# STM32H5F5 register map
File version: 1.0
CPU: CM33 r0p0, little endian, MPU, FPU, 4 interrupt priority bits
Registers are 32-bit, read-write, reset 0x0 unless marked. A register's access mark holds for its fields unless they carry their own. Offsets are from the block's base; [hi:lo] are bit positions; {n}, {i} and the like mark numbered series; 'fields as' and 'values as' point back to an identical list.

## FMC — FMC address block description
Base 0x47000400
Same registers: FMC_S 0x57000400
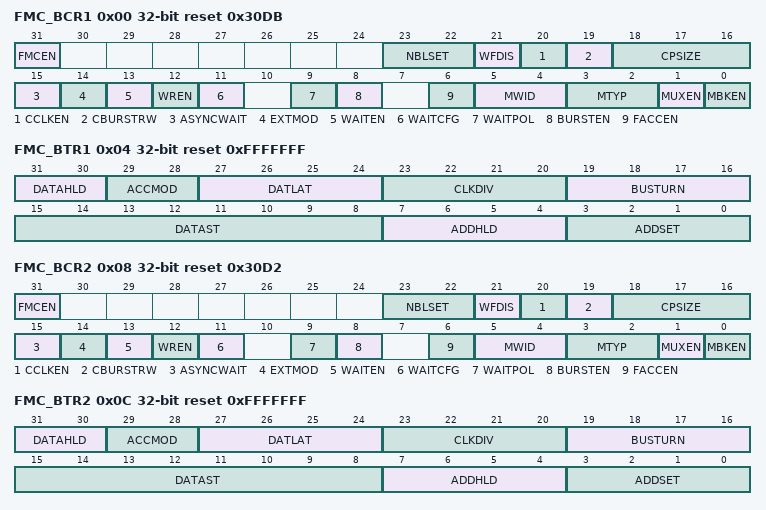
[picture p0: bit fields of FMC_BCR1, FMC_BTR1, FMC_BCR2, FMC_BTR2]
0x00 FMC_BCR1 reset 0x30DB — SRAM/NOR-flash chip-select control register for bank 1
  [31] FMCEN — FMC controller enable
    0=Disable the FMC controller; 1=Enable the FMC controller
  [23:22] NBLSET — Byte lane (NBL) setup
    0=NBL setup time is 0 AHB clock cycle; 1=NBL setup time is 1 AHB clock cycle; 2=NBL setup time is 2 AHB clock cycles; 3=NBL setup time is 3 AHB clock cycles
  [21] WFDIS — Write FIFO disable
    0=Write FIFO enabled (Default after reset); 1=Write FIFO disabled
  [20] CCLKEN — Continuous clock enable
    0=The FMC_CLK is only generated during the synchronous memory access (read/write transaction); 1=The FMC_CLK is generated continuously during asynchronous and synchronous access
  [19] CBURSTRW — Write burst enable
    0=Write operations are always performed in Asynchronous mode; 1=Write operations are performed in Synchronous mode
  [18:16] CPSIZE — CRAM page size
    0=No burst split when crossing page boundary (default after reset); 1=128 bytes; 2=256 bytes; 3=512 bytes; 4=1024 bytes
  [15] ASYNCWAIT — Wait signal during asynchronous transfers
    0=NWAIT signal is not taken in to account when running an asynchronous protocol (default after reset); 1=NWAIT signal is taken in to account when running an asynchronous protocol
  [14] EXTMOD — Extended mode enable
    0=values inside FMC_BWTR register are not taken into account (default after reset); 1=values inside FMC_BWTR register are taken into account
  [13] WAITEN — Wait enable bit
    0=NWAIT signal is disabled (its level not taken into account, no wait state inserted after the programmed flash latency period); 1=NWAIT signal is enabled (its level is taken into account after the programmed latency period to insert wait states if asserted) (default after reset)
  [12] WREN — Write enable bit
    0=Write operations are disabled in the bank by the FMC, an AHB error is reported; 1=Write operations are enabled for the bank by the FMC (default after reset)
  [11] WAITCFG — Wait timing configuration
    0=NWAIT signal is active one data cycle before wait state (default after reset); 1=NWAIT signal is active during wait state (not used for PSRAM)
  [9] WAITPOL — Wait signal polarity bit
    0=NWAIT active low (default after reset); 1=NWAIT active high
  [8] BURSTEN — Burst enable bit
    0=Burst mode disabled (default after reset); 1=Burst mode enable
  [6] FACCEN — Flash access enable
    0=Corresponding NOR flash memory access is disabled; 1=Corresponding NOR flash memory access is enabled (default after reset)
  [5:4] MWID — Memory data bus width
    0=8 bits; 1=16 bits (default after reset); 2=32 bits
  [3:2] MTYP — Memory type
    0=SRAM/FRAM (default after reset for Bank 2; 1=PSRAM (CRAM) / FRAM; 2=NOR flash/OneNAND flash (default after reset for Bank 1)
  [1] MUXEN — Address/data multiplexing enable bit
    0=Address/data non multiplexed; 1=Address/data multiplexed on databus (default after reset)
  [0] MBKEN — Memory bank enable bit
    0=Corresponding memory bank is disabled; 1=Corresponding memory bank is enabled
0x04 FMC_BTR1 reset 0xFFFFFFF — SRAM/NOR-flash chip-select timing register for bank 1
  [31:30] DATAHLD — Data hold phase duration
    0=DATAHLD phase duration = 1 x HCLK clock cycle (default); 1=DATAHLD phase duration = 2 x HCLK clock cycle; 2=DATAHLD phase duration = 3 x HCLK clock cycle; 3=DATAHLD phase duration = 4 x HCLK clock cycle
  [29:28] ACCMOD — Access mode
    0=Access mode A; 1=Access mode B; 2=Access mode C; 3=Access mode D
  [27:24] DATLAT — (see note below bit descriptions): Data latency for synchronous memory
    0=Data latency of 2 CLK clock cycles for first burst access; 15=Data latency of 17 CLK clock cycles for first burst access (default value after reset)
  [23:20] CLKDIV — Clock divide ratio (for FMC_CLK signal)
    0=FMC_CLK period= 1x HCLK period; 1=FMC_CLK period = 2 x HCLK periods; 2=FMC_CLK period = 3 x HCLK periods; 15=FMC_CLK period = 16 x HCLK periods (default value after reset)
  [19:16] BUSTURN — Bus turnaround phase duration
    0=BUSTURN phase duration = 1 HCLK clock cycle added; 15=BUSTURN phase duration = 16 x HCLK clock cycles added (default value after reset)
  [15:8] DATAST — Data-phase duration
    1=DATAST phase duration = 1 x HCLK clock cycles; 2=DATAST phase duration = 2 x HCLK clock cycles; 255=DATAST phase duration = 255 x HCLK clock cycles (default value after reset)
  [7:4] ADDHLD — Address-hold phase duration
    1=ADDHLD phase duration =1 x HCLK clock cycle; 2=ADDHLD phase duration = 2 x HCLK clock cycle; 15=ADDHLD phase duration = 15 x HCLK clock cycles (default value after reset)
  [3:0] ADDSET — Address setup phase duration
    0=ADDSET phase duration = 0 x HCLK clock cycle; 15=ADDSET phase duration = 15 x HCLK clock cycles (default value after reset)
0x08 FMC_BCR2 reset 0x30D2 — SRAM/NOR-flash chip-select control register for bank 2
  fields as FMC_BCR1
0x0C FMC_BTR2 reset 0xFFFFFFF — SRAM/NOR-flash chip-select timing register for bank 2
  fields as FMC_BTR1
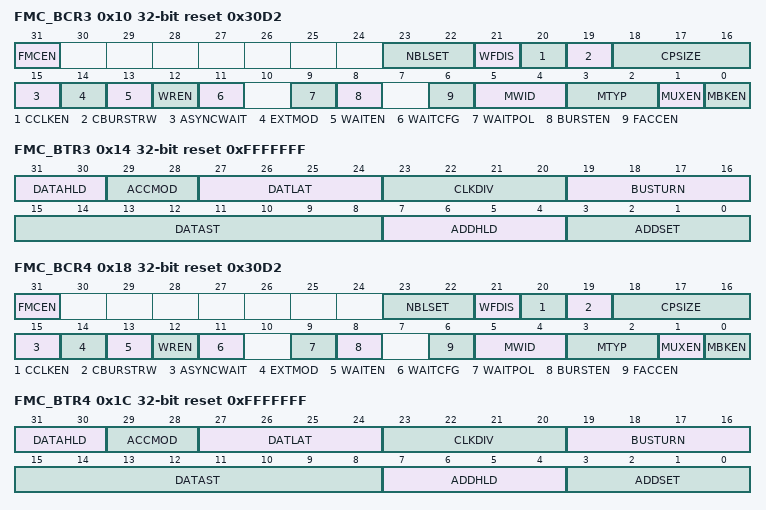
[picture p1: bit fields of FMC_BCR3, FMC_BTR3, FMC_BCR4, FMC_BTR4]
0x10 FMC_BCR3 reset 0x30D2 — SRAM/NOR-flash chip-select control register for bank 3
  fields as FMC_BCR1
0x14 FMC_BTR3 reset 0xFFFFFFF — SRAM/NOR-flash chip-select timing register for bank 3
  fields as FMC_BTR1
0x18 FMC_BCR4 reset 0x30D2 — SRAM/NOR-flash chip-select control register for bank 4
  fields as FMC_BCR1
0x1C FMC_BTR4 reset 0xFFFFFFF — SRAM/NOR-flash chip-select timing register for bank 4
  fields as FMC_BTR1
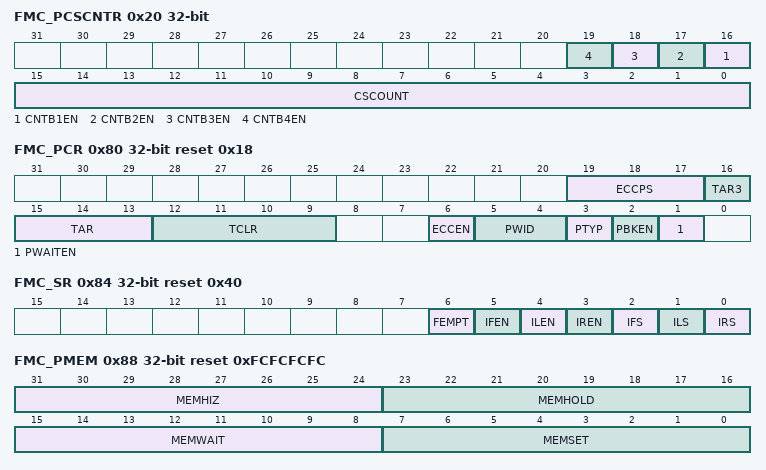
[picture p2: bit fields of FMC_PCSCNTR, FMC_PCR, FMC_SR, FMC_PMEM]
0x20 FMC_PCSCNTR — PSRAM chip select counter register
  [n+15] CNTB{n}EN (n=1..4) — Counter Bank {n} enable
    0=Counter disabled for Bank {n}; 1=Counter enabled for Bank {n}
  [15:0] CSCOUNT — Chip select counter.
0x80 FMC_PCR reset 0x18 — NAND flash control registers
  [19:17] ECCPS — ECC page size
    0=256 bytes; 1=512 bytes; 2=1024 bytes; 3=2048 bytes; 4=4096 bytes; 5=8192 bytes
  [16] TAR3 — ALE to RE delay
    0=1 HCLK cycle (default)
  [15:13] TAR — ALE to RE delay
    0=1 HCLK cycle (default)
  [12:9] TCLR — CLE to RE delay
    0=1 HCLK cycle (default); 15=16 HCLK cycles
  [6] ECCEN — ECC computation logic enable bit
    0=ECC logic is disabled and reset (default after reset),; 1=ECC logic is enabled
  [5:4] PWID — Data bus width
    0=8 bits; 1=16 bits (default after reset)
  [3] PTYP — Memory type
    1=NAND flash (default after reset)
  [2] PBKEN — NAND flash memory bank enable bit
    0=Corresponding memory bank is disabled (default after reset); 1=Corresponding memory bank is enabled
  [1] PWAITEN — Wait feature enable bit
    0=disabled; 1=enabled
0x84 FMC_SR reset 0x40 — FIFO status and interrupt register
  [6] FEMPT ro — FIFO empty
    0=FIFO not empty; 1=FIFO empty
  [5] IFEN — Interrupt falling edge detection enable bit
    0=Interrupt falling edge detection request disabled; 1=Interrupt falling edge detection request enabled
  [4] ILEN — Interrupt high-level detection enable bit
    0=Interrupt high-level detection request disabled; 1=Interrupt high-level detection request enabled
  [3] IREN — Interrupt rising edge detection enable bit
    0=Interrupt rising edge detection request disabled; 1=Interrupt rising edge detection request enabled
  [2] IFS — Interrupt falling edge status
    0=No interrupt falling edge occurred; 1=Interrupt falling edge occurred
  [1] ILS — Interrupt high-level status
    0=No Interrupt high-level occurred; 1=Interrupt high-level occurred
  [0] IRS — Interrupt rising edge status
    0=No interrupt rising edge occurred; 1=Interrupt rising edge occurred
0x88 FMC_PMEM reset 0xFCFCFCFC — Common memory space timing register
  [31:24] MEMHIZ — Common memory x data bus Hi-Z time
    0=1 HCLK cycle; 254=255 HCLK cycles
  [23:16] MEMHOLD — Common memory hold time
    1=1 HCLK cycle for write access / 3 HCLK cycles for read access; 254=254 HCLK cycles for write access / 256 HCLK cycles for read access
  [15:8] MEMWAIT — Common memory wait time
    1=2HCLK cycles (+ wait cycle introduced by deasserting NWAIT); 254=255 HCLK cycles (+ wait cycle introduced by deasserting NWAIT)
  [7:0] MEMSET — Common memory x setup time
    0=1HCLK cycle; 254=255 HCLK cycles
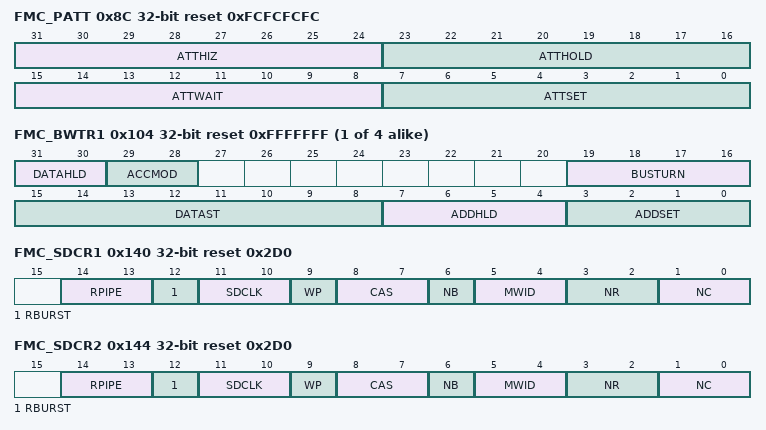
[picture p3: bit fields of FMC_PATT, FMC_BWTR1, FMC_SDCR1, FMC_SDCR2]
0x8C FMC_PATT reset 0xFCFCFCFC — Attribute memory space timing register
  [31:24] ATTHIZ — Attribute memory data bus Hi-Z time
    0=1 HCLK cycle; 254=255 HCLK cycles
  [23:16] ATTHOLD — Attribute memory hold time
    values as FMC_PMEM.MEMHOLD
  [15:8] ATTWAIT — Attribute memory wait time
    1=2 HCLK cycles (+ wait cycle introduced by deassertion of NWAIT); 254=255 HCLK cycles (+ wait cycle introduced by deasserting NWAIT)
  [7:0] ATTSET — Attribute memory setup time
    0=1 HCLK cycle; 254=255 HCLK cycles
0x94 FMC_ECCR ro — ECC result registers
  [31:0] ECC — ECC result
{0xFC+8i} FMC_BWTR{i} reset 0xFFFFFFF (i=1..4) — SRAM/NOR-flash write timing registers {i}
  [31:30] DATAHLD — Data hold phase duration
    values as FMC_BTR1.DATAHLD
  [29:28] ACCMOD — Access mode.
    values as FMC_BTR1.ACCMOD
  [19:16] BUSTURN — Bus turnaround phase duration
    values as FMC_BTR1.BUSTURN
  [15:8] DATAST — Data-phase duration.
    values as FMC_BTR1.DATAST
  [7:4] ADDHLD — Address-hold phase duration.
    1=ADDHLD phase duration = 1 x HCLK clock cycle; 2=ADDHLD phase duration = 2 x HCLK clock cycle; 15=ADDHLD phase duration = 15 x HCLK clock cycles (default value after reset)
  [3:0] ADDSET — Address setup phase duration.
    values as FMC_BTR1.ADDSET
0x140 FMC_SDCR1 reset 0x2D0 — SDRAM control register 1
  [14:13] RPIPE — Read pipe
    0=No clock cycle delay; 1=One clock cycle delay; 2=Two clock cycle delay
  [12] RBURST — Burst read
    0=single read requests are not managed as bursts; 1=single read requests are always managed as bursts
  [11:10] SDCLK — SDRAM clock configuration
    0=SDCLK clock disabled; 2=SDCLK period = 2 x HCLK periods; 3=SDCLK period = 3 x HCLK periods
  [9] WP — Write protection
    0=Write accesses allowed; 1=Write accesses ignored
  [8:7] CAS — CAS Latency
    1=1 cycle; 2=2 cycles; 3=3 cycles
  [6] NB — Number of internal banks
    0=Two internal Banks; 1=Four internal Banks
  [5:4] MWID — Memory data bus width.
    0=8 bits; 1=16 bits; 2=32 bits
  [3:2] NR — Number of row address bits
    0=11 bit; 1=12 bits; 2=13 bits
  [1:0] NC — Number of column address bits
    {v}={v+8} bits (v=0..3)
0x144 FMC_SDCR2 reset 0x2D0 — SDRAM control register 2
  fields as FMC_SDCR1
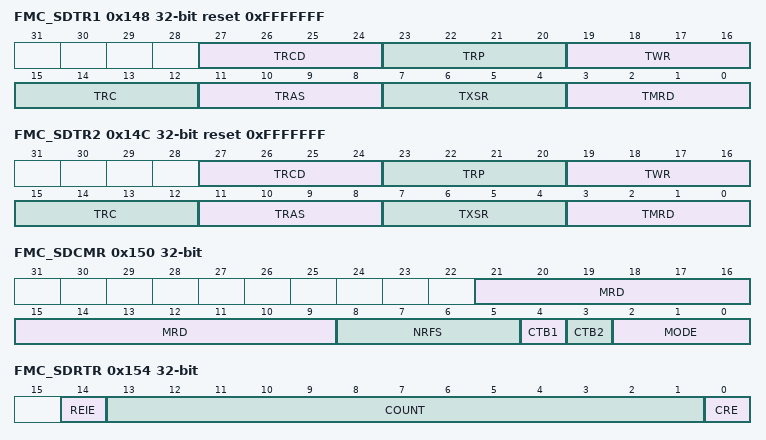
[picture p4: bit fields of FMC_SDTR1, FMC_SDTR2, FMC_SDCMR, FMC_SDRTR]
0x148 FMC_SDTR1 reset 0xFFFFFFF — SDRAM timing register 1
  [all] fields
    0=1 cycle; 1=2 cycles; 15=16 cycles
  [27:24] TRCD — Row to column delay
  [23:20] TRP — Row precharge delay
  [19:16] TWR — Recovery delay
  [15:12] TRC — Row cycle delay
  [11:8] TRAS — Self refresh time
  [7:4] TXSR — Exit Self-refresh delay
  [3:0] TMRD — Load Mode Register to Active
0x14C FMC_SDTR2 reset 0xFFFFFFF — SDRAM timing register 2
  fields as FMC_SDTR1
0x150 FMC_SDCMR — SDRAM Command Mode register
  [21:9] MRD — Mode Register definition
  [8:5] NRFS — Number of Auto-refresh
    0=1 Auto-refresh cycle; 1=2 Auto-refresh cycles; 14=15 Auto-refresh cycles; 15=16 Auto-refresh cycles
  [4] CTB1 wo — Command Target Bank 1
    0=Command not issued to SDRAM Bank 1; 1=Command issued to SDRAM Bank 1
  [3] CTB2 wo — Command Target Bank 2
    0=Command not issued to SDRAM Bank 2; 1=Command issued to SDRAM Bank 2
  [2:0] MODE wo — Command mode
    0=Normal Mode; 1=Clock Configuration Enable; 2=PALL (All Bank Precharge) command; 3=Auto-refresh command; 4=Load Mode Register; 5=Self-refresh command; 6=Power-down command
0x154 FMC_SDRTR — SDRAM refresh timer register
  [14] REIE — RES Interrupt Enable
    0=Interrupt is disabled; 1=An Interrupt is generated if RE = 1
  [13:1] COUNT — Refresh Timer Count
  [0] CRE wo — Clear Refresh error flag
    0=no effect; 1=Refresh Error flag is cleared
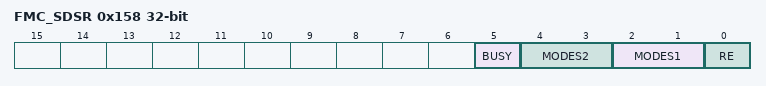
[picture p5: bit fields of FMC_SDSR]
0x158 FMC_SDSR ro — SDRAM status register
  [5] BUSY — Busy status
    0=SDRAM Controller is ready to accept a new request
  [4:3] MODES2 — Status Mode for Bank 2
    0=Normal Mode; 1=Self-refresh mode; 2=Power-down mode
  [2:1] MODES1 — Status Mode for Bank 1
    0=Normal Mode; 1=Self-refresh mode; 2=Power-down mode
  [0] RE — Refresh error flag
    0=No refresh error has been detected; 1=A refresh error has been detected
